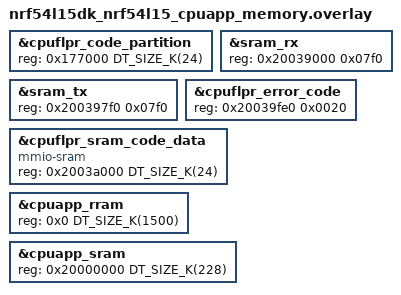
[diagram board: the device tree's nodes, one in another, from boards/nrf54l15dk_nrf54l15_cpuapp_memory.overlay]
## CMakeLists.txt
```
#
# Copyright (c) 2025 Nordic Semiconductor ASA
#
# SPDX-License-Identifier: LicenseRef-Nordic-5-Clause
#

cmake_minimum_required(VERSION 3.20.0)

find_package(Zephyr REQUIRED HINTS $ENV{ZEPHYR_BASE})
project(hpf_app_trap_handler)

target_sources(app PRIVATE src/main.c)
```

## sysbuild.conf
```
#
# Copyright (c) 2025 Nordic Semiconductor ASA
#
# SPDX-License-Identifier: LicenseRef-Nordic-5-Clause
#

SB_CONFIG_VPR_LAUNCHER=n
SB_CONFIG_PARTITION_MANAGER=n
SB_CONFIG_HPF=y
SB_CONFIG_HPF_MSPI=y

# Enable HPF developer mode to disable CI errors.
# It is related to rebuilding the asm part after enabling ASSERT.
SB_CONFIG_HPF_DEVELOPER_MODE=y
```

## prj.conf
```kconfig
#
# Copyright (c) 2025 Nordic Semiconductor ASA
#
# SPDX-License-Identifier: LicenseRef-Nordic-5-Clause
#

CONFIG_TEST=y
CONFIG_ZTEST=y
CONFIG_FLASH=y
CONFIG_FLASH_PAGE_LAYOUT=y
CONFIG_MAIN_STACK_SIZE=2048
CONFIG_ZTEST_STACK_SIZE=4096
```

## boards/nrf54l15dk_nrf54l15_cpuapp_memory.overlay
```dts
/*
 * Copyright (c) 2025 Nordic Semiconductor ASA
 *
 * SPDX-License-Identifier: LicenseRef-Nordic-5-Clause
 */

&cpuflpr_code_partition {
	reg = <0x177000 DT_SIZE_K(24)>;
};

&sram_rx {
	reg = <0x20039000 0x07f0>;
};

&sram_tx {
	reg = <0x200397f0 0x07f0>;
};

&cpuflpr_error_code {
	reg = <0x20039fe0 0x0020>; /* 32bytes */
};

&cpuflpr_sram_code_data {
	compatible = "mmio-sram";
	reg = <0x2003a000 DT_SIZE_K(24)>;
	#address-cells = <1>;
	#size-cells = <1>;
	ranges = <0x0 0x2003a000 0x6000>;
};

&cpuapp_rram {
	reg = <0x0 DT_SIZE_K(1500)>;
};

&cpuapp_sram {
	reg = <0x20000000 DT_SIZE_K(228)>;
	ranges = <0x0 0x20000000 0x39000>;
};
```

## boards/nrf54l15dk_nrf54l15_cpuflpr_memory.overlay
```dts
/*
 * Copyright (c) 2025 Nordic Semiconductor ASA
 *
 * SPDX-License-Identifier: LicenseRef-Nordic-5-Clause
 */

&sram_tx {
	reg = <0x20039000 0x07f0>;
};

&sram_rx {
	reg = <0x200397f0 0x07f0>;
};

&cpuflpr_error_code {
	reg = <0x20039fe0 0x0020>; /* 32bytes */
};

&cpuflpr_rram {
	reg = <0x177000 DT_SIZE_K(24)>;
};

&cpuflpr_code_partition {
	reg = <0x0 DT_SIZE_K(24)>;
};

&cpuflpr_sram {
	reg = <0x2003a000 DT_SIZE_K(24)>;
	ranges = <0x0 0x2003a000 0x6000>;
};
```

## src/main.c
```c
/*
 * Copyright (c) 2025 Nordic Semiconductor ASA
 *
 * SPDX-License-Identifier: LicenseRef-Nordic-5-Clause
 */

#include <zephyr/device.h>
#include <zephyr/drivers/mspi.h>
#include <zephyr/drivers/mspi_emul.h>
#include <zephyr/ztest.h>

#define MSPI_BUS_NODE DT_NODELABEL(hpf_mspi)

static const struct device *mspi_devices[] = {
	DT_FOREACH_CHILD_STATUS_OKAY_SEP(MSPI_BUS_NODE, DEVICE_DT_GET, (,))
};

static struct mspi_dev_cfg device_cfg[] = {
	DT_FOREACH_CHILD_STATUS_OKAY_SEP(MSPI_BUS_NODE, MSPI_DEVICE_CONFIG_DT, (,))
};

ZTEST(hpf_trap_handler, test_trap_handler)
{
	int ret = 0;
	const struct device *mspi_bus = DEVICE_DT_GET(MSPI_BUS_NODE);
	const struct mspi_dev_id dev_id = {
		.dev_idx = 0xFF,
	};

	zassert_true(device_is_ready(mspi_bus), "mspi_bus is not ready");
	zassert_true(device_is_ready(mspi_devices[0]), "mspi_device is not ready");

	/* Push wrong device id to trigger assert on flpr app side */
	ret = mspi_dev_config(mspi_bus, &dev_id, MSPI_DEVICE_CONFIG_ALL, &device_cfg[0]);
	zassert_equal(ret, -ETIMEDOUT, "Assert not triggered?");
}

ZTEST_SUITE(hpf_trap_handler, NULL, NULL, NULL, NULL, NULL);
```
